VERSION "Detroit_J1939_Proprietary_v2.0"

NS_ :

BS_:

BU_: ECM_DDD

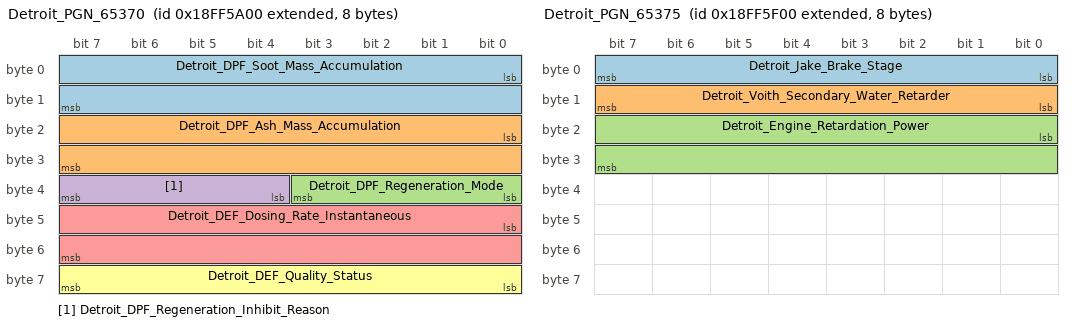
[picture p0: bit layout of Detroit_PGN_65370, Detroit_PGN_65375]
BO_ 2566871552 Detroit_PGN_65370: 8 ECM_DDD
 SG_ Detroit_DPF_Soot_Mass_Accumulation : 0|16@1+ (0.1,0) [0|6553.5] "g" Vector__XXX
 SG_ Detroit_DPF_Ash_Mass_Accumulation : 16|16@1+ (1,0) [0|65535] "g" Vector__XXX
 SG_ Detroit_DPF_Regeneration_Mode : 32|4@1+ (1,0) [0|15] "" Vector__XXX
 SG_ Detroit_DPF_Regeneration_Inhibit_Reason : 36|4@1+ (1,0) [0|15] "" Vector__XXX
 SG_ Detroit_DEF_Dosing_Rate_Instantaneous : 40|16@1+ (0.1,0) [0|6553.5] "g/min" Vector__XXX
 SG_ Detroit_DEF_Quality_Status : 56|8@1+ (1,0) [0|255] "" Vector__XXX

BO_ 2566872832 Detroit_PGN_65375: 8 ECM_DDD
 SG_ Detroit_Jake_Brake_Stage : 0|8@1+ (1,0) [0|255] "" Vector__XXX
 SG_ Detroit_Voith_Secondary_Water_Retarder : 8|8@1+ (0.4,0) [0|102] "%" Vector__XXX
 SG_ Detroit_Engine_Retardation_Power : 16|16@1+ (0.1,0) [0|6553.5] "kW" Vector__XXX

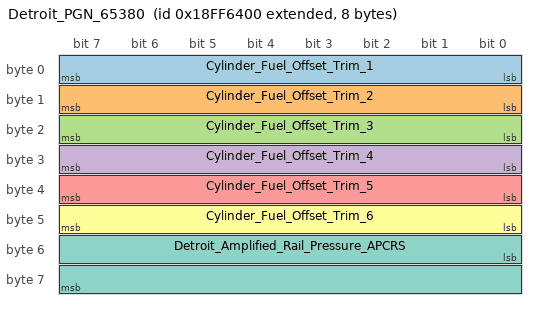
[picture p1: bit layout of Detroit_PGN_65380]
BO_ 2566874112 Detroit_PGN_65380: 8 ECM_DDD
 SG_ Cylinder_Fuel_Offset_Trim_1 : 0|8@1+ (0.05,-6.4) [-6.4|6.35] "mg/stroke" Vector__XXX
 SG_ Cylinder_Fuel_Offset_Trim_2 : 8|8@1+ (0.05,-6.4) [-6.4|6.35] "mg/stroke" Vector__XXX
 SG_ Cylinder_Fuel_Offset_Trim_3 : 16|8@1+ (0.05,-6.4) [-6.4|6.35] "mg/stroke" Vector__XXX
 SG_ Cylinder_Fuel_Offset_Trim_4 : 24|8@1+ (0.05,-6.4) [-6.4|6.35] "mg/stroke" Vector__XXX
 SG_ Cylinder_Fuel_Offset_Trim_5 : 32|8@1+ (0.05,-6.4) [-6.4|6.35] "mg/stroke" Vector__XXX
 SG_ Cylinder_Fuel_Offset_Trim_6 : 40|8@1+ (0.05,-6.4) [-6.4|6.35] "mg/stroke" Vector__XXX
 SG_ Detroit_Amplified_Rail_Pressure_APCRS : 48|16@1+ (0.1,0) [0|6553.5] "MPa" Vector__XXX

BA_DEF_ BO_  "J1939PGN" INT 0 262143;
BA_DEF_DEF_  "J1939PGN" 0;
CM_ SG_ 2566871552 Detroit_DPF_Regeneration_Mode "enum values: see Detroit decoder MAP in project source";
CM_ SG_ 2566871552 Detroit_DPF_Regeneration_Inhibit_Reason "enum values: see Detroit decoder MAP in project source";
CM_ SG_ 2566871552 Detroit_DEF_Quality_Status "enum values: see Detroit decoder MAP in project source";
CM_ BO_ 2566871552 "PGN 65370 (0xFF5A): Detroit proprietary layout derived from project OEM decoder";
CM_ SG_ 2566872832 Detroit_Jake_Brake_Stage "enum values: see Detroit decoder MAP in project source";
CM_ BO_ 2566872832 "PGN 65375 (0xFF5F): Detroit proprietary layout derived from project OEM decoder";
CM_ BO_ 2566874112 "PGN 65380 (0xFF64): Detroit proprietary layout derived from project OEM decoder";
BA_ "J1939PGN" BO_ 2566871552 65370;
BA_ "J1939PGN" BO_ 2566872832 65375;
BA_ "J1939PGN" BO_ 2566874112 65380;
